# STM32G4A1xx register map
File version: 1.0
Registers are 32-bit, access not given, reset 0x0 unless marked. A register's access mark holds for its fields unless they carry their own. Offsets are from the block's base; [hi:lo] are bit positions; {n}, {i} and the like mark numbered series.

## SYSCFG
Base 0x40010000
0x00 MEMRMP
  [22] I2C3_FMP, [21] I2C2_FMP, [20] I2C1_FMP, [n+10] I2C_PB{n}_FMP (n=6..9), [n] PAGE{n} (n=0..15), [4n+2:4n] EXTI{n} (n=0..3), [4n-14:4n-16] EXTI{n} (n=4..7), [4n-30:4n-32] EXTI{n} (n=8..11), [4n-46:4n-48] EXTI{n} (n=12..15), [9] ANASWVDD, [8] FB_MODE, [8] BOOSTEN, [8] SPF, [3] ECCL, [2] PVDL, [1] CCMBSY, [1] SPL, [2:0] MEM_MODE, [0] CCMER, [0] CLL, [7:0] KEY
0x04 CFGR1
0x08 EXTICR.0
0x0C EXTICR.1
0x10 EXTICR.2
0x14 EXTICR.3
0x18 SCSR
0x1C CFGR2
0x20 SWPR
0x24 SKR

## VREFBUF
Base 0x40010030
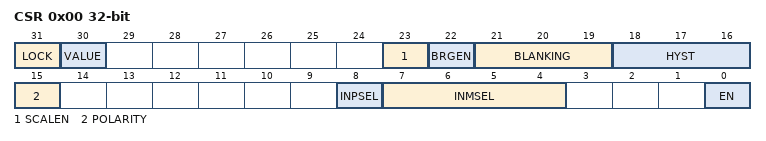
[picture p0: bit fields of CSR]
0x00 CSR
  [5:4] VRS, [3] VRR, [1] HIZ, [0] ENVR, [5:0] TRIM
0x04 CCR

## COMP1
Base 0x40010200
Same registers: COMP2 0x40010204, COMP3 0x40010208, COMP4 0x4001020C
0x00 CSR
  [31] LOCK, [30] VALUE, [23] SCALEN, [22] BRGEN, [21:19] BLANKING, [18:16] HYST, [15] POLARITY, [8] INPSEL, [7:4] INMSEL, [0] EN

## OPAMP
Base 0x40010300
0x00 CSR
  [31] LOCK, [31] LOCK, [30] OUTCAL, [28:24] TRIMOFFSETN, [23:19] TRIMOFFSETP, [18:14] PGGAIN, [13:12] CALSEL, [11] CALON, [8] OPAMPINTEN, [7] HIGHSPEEDEN, [6:5] VMSEL, [5] T20CMEN, [4] USERTRIM, [4] T8CMEN, [3] T1CMEN, [3:2] VPSEL, [1] FORCEVP, [2:1] VPSSEL, [0] OPAMPxEN, [0] VMSSEL
0x18 TCMR

## OPAMP1
Base 0x40010300
Same registers: OPAMP2 0x40010304, OPAMP3 0x40010308, OPAMP6 0x40010314
0x00 CSR
  [31] LOCK, [31] LOCK, [30] OUTCAL, [28:24] TRIMOFFSETN, [23:19] TRIMOFFSETP, [18:14] PGGAIN, [13:12] CALSEL, [11] CALON, [8] OPAMPINTEN, [7] HIGHSPEEDEN, [6:5] VMSEL, [5] T20CMEN, [4] USERTRIM, [4] T8CMEN, [3] T1CMEN, [3:2] VPSEL, [1] FORCEVP, [2:1] VPSSEL, [0] OPAMPxEN, [0] VMSSEL
0x18 TCMR

## EXTI
Base 0x40010400
0x00 IMR1
  [n] IM{n} (n=0..30), [n] EM{n} (n=0..30), [30] RT30, [30] FT30, [30] SWI30, [30] PIF30, [29] RT29, [29] FT29, [29] SWI29, [29] PIF29, [n] RT{n} (n=19..22), [n] FT{n} (n=19..22), [n] SWI{n} (n=19..22), [n] PIF{n} (n=19..22), [n] RT{n} (n=0..17), [n] FT{n} (n=0..17), [n] SWI{n} (n=0..17), [n] PIF{n} (n=0..17), [n-32] IM{n} (n=34..41), [n-32] EM{n} (n=36..41), [n-32] RT{n} (n=38..41), [n-32] FT{n} (n=38..41), [n-32] SWI{n} (n=38..41), [n-32] PIF{n} (n=38..41), [2] EM34, [9:0] IM, [9:0] EM
0x04 EMR1
0x08 RTSR1
0x0C FTSR1
0x10 SWIER1
0x14 PR1
0x20 IMR2
0x24 EMR2
0x28 RTSR2
0x2C FTSR2
0x30 SWIER2
0x34 PR2

## SAI1
Base 0x40015400
0x00 GCR
  [8n-2:8n-4] DLYM{n}R (n=1..4), [8n-6:8n-8] DLYM{n}L (n=1..4), [n+7] CKEN{n} (n=1..4), [5:4] SYNCOUT, [5:4] MICNBR, [1:0] SYNCIN, [0] PDMEN
0x04 CR1A
0x08 CR2A
0x10 FRCRA
0x1C SLOTRA
0x24 CR1B
0x28 CR2B
0x2C IMRA
0x30 FRCRB
0x3C SLOTRB
0x40 SRA
0x44 PDMCR
0x48 PDMDLY
0x4C IMRB
0x58 CLRFRA
0x60 SRB
0x74 DRA
0x78 CLRFRB
0x94 DRB

## DMA1
Base 0x40020000
Same registers: DMA2 0x40020400
0x00 ISR
  [4n-1] TEIF{n} (n=1..8), [4n-1] CTEIF{n} (n=1..8), [4n-2] HTIF{n} (n=1..8), [4n-2] CHTIF{n} (n=1..8), [4n-3] TCIF{n} (n=1..8), [4n-3] CTCIF{n} (n=1..8), [4n-4] GIF{n} (n=1..8), [4n-4] CGIF{n} (n=1..8), [14] MEM2MEM, [14] MEM2MEM, [14] MEM2MEM, [14] MEM2MEM, [14] MEM2MEM, [14] MEM2MEM, [14] MEM2MEM, [14] MEM2MEM, [14] MEM2MEM, [14] MEM2MEM, [14] MEM2MEM, [14] MEM2MEM, [14] MEM2MEM, [14] MEM2MEM, [14] MEM2MEM, [14] MEM2MEM, [13:12] PL, [13:12] PL, [13:12] PL, [13:12] PL, [13:12] PL, [13:12] PL, [13:12] PL, [13:12] PL, [13:12] PL, [13:12] PL, [13:12] PL, [13:12] PL, [13:12] PL, [13:12] PL, [13:12] PL, [13:12] PL, [11:10] MSIZE, [11:10] MSIZE, [11:10] MSIZE, [11:10] MSIZE, [11:10] MSIZE, [11:10] MSIZE, [11:10] MSIZE, [11:10] MSIZE, [11:10] MSIZE, [11:10] MSIZE, [11:10] MSIZE, [11:10] MSIZE, [11:10] MSIZE, [11:10] MSIZE, [11:10] MSIZE, [11:10] MSIZE, [9:8] PSIZE, [9:8] PSIZE, [9:8] PSIZE, [9:8] PSIZE, [9:8] PSIZE, [9:8] PSIZE, [9:8] PSIZE, [9:8] PSIZE, [9:8] PSIZE, [9:8] PSIZE, [9:8] PSIZE, [9:8] PSIZE, [9:8] PSIZE, [9:8] PSIZE, [9:8] PSIZE, [9:8] PSIZE, [7] MINC, [7] MINC, [7] MINC, [7] MINC, [7] MINC, [7] MINC, [7] MINC, [7] MINC, [7] MINC, [7] MINC, [7] MINC, [7] MINC, [7] MINC, [7] MINC, [7] MINC, [7] MINC, [6] PINC, [6] PINC, [6] PINC, [6] PINC, [6] PINC, [6] PINC, [6] PINC, [6] PINC, [6] PINC, [6] PINC, [6] PINC, [6] PINC, [6] PINC, [6] PINC, [6] PINC, [6] PINC, [5] CIRC, [5] CIRC, [5] CIRC, [5] CIRC, [5] CIRC, [5] CIRC, [5] CIRC, [5] CIRC, [5] CIRC, [5] CIRC, [5] CIRC, [5] CIRC, [5] CIRC, [5] CIRC, [5] CIRC, [5] CIRC, [4] DIR, [4] DIR, [4] DIR, [4] DIR, [4] DIR, [4] DIR, [4] DIR, [4] DIR, [4] DIR, [4] DIR, [4] DIR, [4] DIR, [4] DIR, [4] DIR, [4] DIR, [4] DIR, [3] TEIE, [3] TEIE, [3] TEIE, [3] TEIE, [3] TEIE, [3] TEIE, [3] TEIE, [3] TEIE, [3] TEIE, [3] TEIE, [3] TEIE, [3] TEIE, [3] TEIE, [3] TEIE, [3] TEIE, [3] TEIE, [2] HTIE, [2] HTIE, [2] HTIE, [2] HTIE, [2] HTIE, [2] HTIE, [2] HTIE, [2] HTIE, [2] HTIE, [2] HTIE, [2] HTIE, [2] HTIE, [2] HTIE, [2] HTIE, [2] HTIE, [2] HTIE, [1] TCIE, [1] TCIE, [1] TCIE, [1] TCIE, [1] TCIE, [1] TCIE, [1] TCIE, [1] TCIE, [1] TCIE, [1] TCIE, [1] TCIE, [1] TCIE, [1] TCIE, [1] TCIE, [1] TCIE, [1] TCIE, [0] EN, [0] EN, [15:0] NDT, [15:0] NDT, [31:0] PA, [31:0] PA, [0] EN, [0] EN, [31:0] MA, [15:0] NDT, [31:0] MA, [15:0] NDT, [31:0] PA, [31:0] PA, [0] EN, [0] EN, [31:0] MA, [15:0] NDT, [31:0] MA, [15:0] NDT, [31:0] PA, [31:0] PA, [0] EN, [0] EN, [31:0] MA, [15:0] NDT, [31:0] MA, [15:0] NDT, [31:0] PA, [31:0] PA, [0] EN, [0] EN, [31:0] MA, [15:0] NDT, [31:0] MA, [15:0] NDT, [31:0] PA, [31:0] PA, [0] EN, [0] EN, [31:0] MA, [15:0] NDT, [31:0] MA, [15:0] NDT, [31:0] PA, [31:0] PA, [0] EN, [0] EN, [31:0] MA, [15:0] NDT, [31:0] MA, [15:0] NDT, [31:0] PA, [31:0] PA, [0] EN, [0] EN, [31:0] MA, [15:0] NDT, [31:0] MA, [15:0] NDT, [31:0] PA, [31:0] PA, [31:0] MA, [31:0] MA
0x04 IFCR
0x08 CCR1
0x0C CNDTR1
{0x0+0x14*i} CPAR{i} (i=1..8)
0x1C CCR2
{0xC+0x14*i} CMAR{i} (i=1..8)
0x20 CNDTR2
0x30 CCR3
0x34 CNDTR3
0x44 CCR4
0x48 CNDTR4
0x58 CCR5
0x5C CNDTR5
0x6C CCR6
0x70 CNDTR6
0x80 CCR7
0x84 CNDTR7
0x94 CCR8
0x98 CNDTR8
